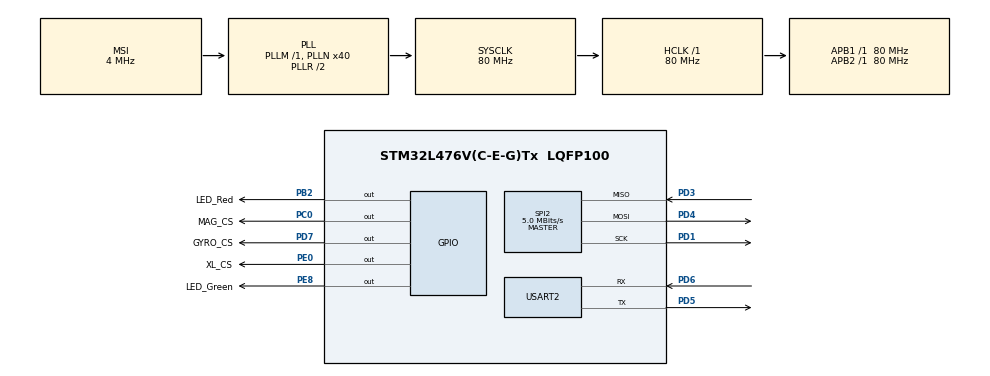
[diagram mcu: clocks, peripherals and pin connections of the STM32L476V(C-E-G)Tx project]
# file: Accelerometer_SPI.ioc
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Dma.Request0=USART2_RX
Dma.Request1=USART2_TX
Dma.USART2_RX.0.Direction=DMA_PERIPH_TO_MEMORY
Dma.USART2_RX.0.Instance=DMA1_Channel6
Dma.USART2_RX.0.MemDataAlignment=DMA_MDATAALIGN_BYTE
Dma.USART2_RX.0.MemInc=DMA_MINC_ENABLE
Dma.USART2_RX.0.Mode=DMA_NORMAL
Dma.USART2_RX.0.PeriphDataAlignment=DMA_PDATAALIGN_BYTE
Dma.USART2_RX.0.PeriphInc=DMA_PINC_DISABLE
Dma.USART2_RX.0.Priority=DMA_PRIORITY_LOW
Dma.USART2_TX.1.Direction=DMA_MEMORY_TO_PERIPH
Dma.USART2_TX.1.Instance=DMA1_Channel7
Dma.USART2_TX.1.MemDataAlignment=DMA_MDATAALIGN_BYTE
Dma.USART2_TX.1.MemInc=DMA_MINC_ENABLE
Dma.USART2_TX.1.Mode=DMA_NORMAL
Dma.USART2_TX.1.PeriphDataAlignment=DMA_PDATAALIGN_BYTE
Dma.USART2_TX.1.PeriphInc=DMA_PINC_DISABLE
Dma.USART2_TX.1.Priority=DMA_PRIORITY_LOW
Mcu.Family=STM32L4
Mcu.Name=STM32L476V(C-E-G)Tx
Mcu.Package=LQFP100
NVIC.DMA1_Channel6_IRQn=true\:0\:0\:false\:false\:true\:false\:true
NVIC.DMA1_Channel7_IRQn=true\:0\:0\:false\:false\:true\:false\:true
NVIC.PriorityGroup=NVIC_PRIORITYGROUP_4
NVIC.SPI2_IRQn=true\:0\:0\:false\:false\:true\:true\:true
NVIC.USART2_IRQn=true\:0\:0\:false\:false\:true\:true\:true
PB2.GPIO_Label=LED_Red
PB2.Signal=GPIO_Output
PC0.GPIO_Label=MAG_CS
PC0.GPIO_Speed=GPIO_SPEED_FREQ_HIGH
PC0.PinState=GPIO_PIN_SET
PC0.Signal=GPIO_Output
PD1.Mode=Full_Duplex_Master
PD1.Signal=SPI2_SCK
PD3.Mode=Full_Duplex_Master
PD3.Signal=SPI2_MISO
PD4.Mode=Full_Duplex_Master
PD4.Signal=SPI2_MOSI
PD5.Mode=Asynchronous
PD5.Signal=USART2_TX
PD6.Mode=Asynchronous
PD6.Signal=USART2_RX
PD7.GPIO_Label=GYRO_CS
PD7.GPIO_Speed=GPIO_SPEED_FREQ_HIGH
PD7.PinState=GPIO_PIN_SET
PD7.Signal=GPIO_Output
PE0.GPIO_Label=XL_CS
PE0.GPIO_Speed=GPIO_SPEED_FREQ_HIGH
PE0.PinState=GPIO_PIN_SET
PE0.Signal=GPIO_Output
PE8.GPIO_Label=LED_Green
PE8.Signal=GPIO_Output
ProjectManager.HeapSize=0x200
ProjectManager.StackSize=0x400
ProjectManager.TargetToolchain=SW4STM32
RCC.AHBFreq_Value=80000000
RCC.APB1Freq_Value=80000000
RCC.APB1TimFreq_Value=80000000
RCC.APB2Freq_Value=80000000
RCC.APB2TimFreq_Value=80000000
RCC.CortexFreq_Value=80000000
RCC.HCLKFreq_Value=80000000
RCC.HSE_VALUE=8000000
RCC.HSI_VALUE=16000000
RCC.LSE_VALUE=32768
RCC.MSI_VALUE=4000000
RCC.PLLN=40
RCC.SYSCLKFreq_VALUE=80000000
RCC.SYSCLKSource=RCC_SYSCLKSOURCE_PLLCLK
RCC.VCOOutputFreq_Value=160000000
SPI2.BaudRatePrescaler=SPI_BAUDRATEPRESCALER_16
SPI2.CLKPhase=SPI_PHASE_2EDGE
SPI2.CLKPolarity=SPI_POLARITY_HIGH
SPI2.CalculateBaudRate=5.0 MBits/s
SPI2.DataSize=SPI_DATASIZE_8BIT
SPI2.Direction=SPI_DIRECTION_2LINES
SPI2.Mode=SPI_MODE_MASTER
SPI2.VirtualType=VM_MASTER
USART2.VirtualMode-Asynchronous=VM_ASYNC
board=custom

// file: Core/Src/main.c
/* USER CODE BEGIN Header */
/**
  ******************************************************************************
  * @file           : main.c
  * @brief          : Main program body
  ******************************************************************************
  * @attention
  *
  * <h2><center>&copy; Copyright (c) 2021 STMicroelectronics.
  * All rights reserved.</center></h2>
  *
  * This software component is licensed by ST under BSD 3-Clause license,
  * the "License"; You may not use this file except in compliance with the
  * License. You may obtain a copy of the License at:
  *                        opensource.org/licenses/BSD-3-Clause
  *
  ******************************************************************************
  */
/* USER CODE END Header */
#include "main.h"
#include "dma.h"
#include "spi.h"
#include "usart.h"
#include "gpio.h"

/* USER CODE BEGIN Includes */
//#include "l3gd20h_reg.h"
//#include "l3gd20_add.h"
#include "l3gd20h_reg.h"
#include "l3gd20_add.h"
/* USER CODE END Includes */

/* USER CODE BEGIN PD */
#define UART_Buffor 10
/* USER CODE END PD */

/* USER CODE BEGIN PV */
uint8_t Received[UART_Buffor];
/* USER CODE END PV */

void SystemClock_Config(void);

int main(void)
{

  /* MCU Configuration--------------------------------------------------------*/

  /* Reset of all peripherals, Initializes the Flash interface and the Systick. */
  HAL_Init();

  /* Configure the system clock */
  SystemClock_Config();

  /* Initialize all configured peripherals */
  MX_GPIO_Init();
  MX_DMA_Init();
  MX_SPI2_Init();
  MX_USART2_UART_Init();
  /* USER CODE BEGIN 2 */
HAL_UART_Receive_DMA(&huart2, Received, UART_Buffor);
l3gd20_init();
  /* USER CODE END 2 */

  /* Infinite loop */
  /* USER CODE BEGIN WHILE */

  while (1)
  {
	  HAL_Delay(200);
	  int32_t error_check;
	  error_check = l3gd20_ReadAngularData();

	  if (error_check !=0)
	  	    {
	  	    	uint32_t size;
	  	    		size = sprintf((char*)tx_buffer, "Error kurwa! \r\n");
	  	    		tx_com(tx_buffer, size);
	  	    }

    /* USER CODE END WHILE */

  }
}

void SystemClock_Config(void)
{
  RCC_OscInitTypeDef RCC_OscInitStruct = {0};
  RCC_ClkInitTypeDef RCC_ClkInitStruct = {0};
  RCC_PeriphCLKInitTypeDef PeriphClkInit = {0};

  /** Initializes the RCC Oscillators according to the specified parameters
  * in the RCC_OscInitTypeDef structure.
  */
  RCC_OscInitStruct.OscillatorType = RCC_OSCILLATORTYPE_MSI;
  RCC_OscInitStruct.MSIState = RCC_MSI_ON;
  RCC_OscInitStruct.MSICalibrationValue = 0;
  RCC_OscInitStruct.MSIClockRange = RCC_MSIRANGE_6;
  RCC_OscInitStruct.PLL.PLLState = RCC_PLL_ON;
  RCC_OscInitStruct.PLL.PLLSource = RCC_PLLSOURCE_MSI;
  RCC_OscInitStruct.PLL.PLLM = 1;
  RCC_OscInitStruct.PLL.PLLN = 40;
  RCC_OscInitStruct.PLL.PLLP = RCC_PLLP_DIV7;
  RCC_OscInitStruct.PLL.PLLQ = RCC_PLLQ_DIV2;
  RCC_OscInitStruct.PLL.PLLR = RCC_PLLR_DIV2;
  if (HAL_RCC_OscConfig(&RCC_OscInitStruct) != HAL_OK)
  {
    Error_Handler();
  }
  /** Initializes the CPU, AHB and APB buses clocks
  */
  RCC_ClkInitStruct.ClockType = RCC_CLOCKTYPE_HCLK|RCC_CLOCKTYPE_SYSCLK
                              |RCC_CLOCKTYPE_PCLK1|RCC_CLOCKTYPE_PCLK2;
  RCC_ClkInitStruct.SYSCLKSource = RCC_SYSCLKSOURCE_PLLCLK;
  RCC_ClkInitStruct.AHBCLKDivider = RCC_SYSCLK_DIV1;
  RCC_ClkInitStruct.APB1CLKDivider = RCC_HCLK_DIV1;
  RCC_ClkInitStruct.APB2CLKDivider = RCC_HCLK_DIV1;

  if (HAL_RCC_ClockConfig(&RCC_ClkInitStruct, FLASH_LATENCY_4) != HAL_OK)
  {
    Error_Handler();
  }
  PeriphClkInit.PeriphClockSelection = RCC_PERIPHCLK_USART2;
  PeriphClkInit.Usart2ClockSelection = RCC_USART2CLKSOURCE_PCLK1;
  if (HAL_RCCEx_PeriphCLKConfig(&PeriphClkInit) != HAL_OK)
  {
    Error_Handler();
  }
  /** Configure the main internal regulator output voltage
  */
  if (HAL_PWREx_ControlVoltageScaling(PWR_REGULATOR_VOLTAGE_SCALE1) != HAL_OK)
  {
    Error_Handler();
  }
}

void Error_Handler(void)
{
  __disable_irq();
  while (1)
  {
  }
}

/************************ (C) COPYRIGHT STMicroelectronics *****END OF FILE****/
